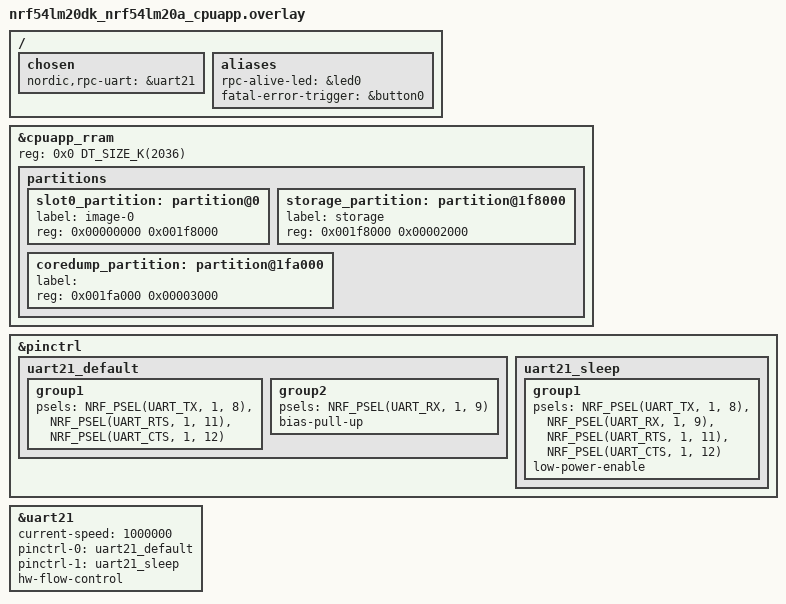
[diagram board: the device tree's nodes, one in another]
/*
 * Copyright (c) 2025 Nordic Semiconductor ASA
 *
 * SPDX-License-Identifier: LicenseRef-Nordic-5-Clause
 */

/ {
	chosen {
		nordic,rpc-uart = &uart21;
	};

	aliases {
		rpc-alive-led = &led0;
		fatal-error-trigger = &button0;

		/* delete all buttons except button0 to free GPIO pins assigned to uart21 below */
		/delete-property/ sw1;
		/delete-property/ sw2;
		/delete-property/ sw3;
	};
};

/delete-node/ &button1;
/delete-node/ &button2;
/delete-node/ &button3;
/delete-node/ &boot_partition;
/delete-node/ &slot0_partition;
/delete-node/ &slot1_partition;
/delete-node/ &storage_partition;

&cpuapp_rram {
	reg = <0x0 DT_SIZE_K(2036)>;

	partitions {
		slot0_partition: partition@0  {
			label = "image-0";
			reg = <0x00000000 0x001f8000>;
		};
		storage_partition: partition@1f8000 {
			label = "storage";
			reg = <0x001f8000 0x00002000>;
		};

		coredump_partition: partition@1fa000 {
			label = "";
			reg = <0x001fa000 0x00003000>;
		};
	};
};

&pinctrl {
	uart21_default: uart21_default {
		group1 {
			psels = <NRF_PSEL(UART_TX, 1, 8)>,
				<NRF_PSEL(UART_RTS, 1, 11)>,
				<NRF_PSEL(UART_CTS, 1, 12)>;
		};
		group2 {
			psels = <NRF_PSEL(UART_RX, 1, 9)>;
			bias-pull-up;
		};
	};

	uart21_sleep: uart21_sleep {
		group1 {
			psels = <NRF_PSEL(UART_TX, 1, 8)>,
				<NRF_PSEL(UART_RX, 1, 9)>,
				<NRF_PSEL(UART_RTS, 1, 11)>,
				<NRF_PSEL(UART_CTS, 1, 12)>;
			low-power-enable;
		};
	};
};

&uart21 {
	status = "okay";
	current-speed = <1000000>;
	pinctrl-0 = <&uart21_default>;
	pinctrl-1 = <&uart21_sleep>;
	pinctrl-names = "default", "sleep";
	hw-flow-control;
};
